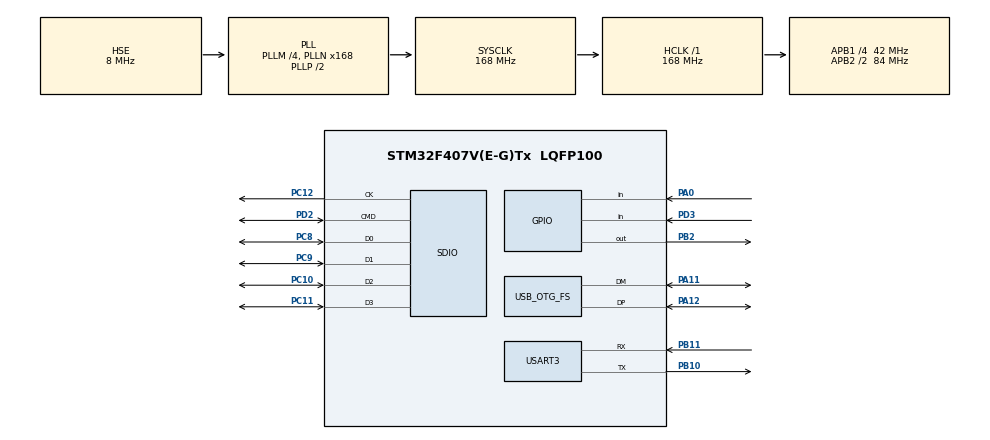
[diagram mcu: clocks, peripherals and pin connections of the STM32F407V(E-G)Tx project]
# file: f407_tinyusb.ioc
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Dma.Request0=USART3_RX
Dma.Request1=USART3_TX
Dma.USART3_RX.0.Direction=DMA_PERIPH_TO_MEMORY
Dma.USART3_RX.0.FIFOMode=DMA_FIFOMODE_DISABLE
Dma.USART3_RX.0.Instance=DMA1_Stream1
Dma.USART3_RX.0.MemDataAlignment=DMA_MDATAALIGN_BYTE
Dma.USART3_RX.0.MemInc=DMA_MINC_ENABLE
Dma.USART3_RX.0.Mode=DMA_NORMAL
Dma.USART3_RX.0.PeriphDataAlignment=DMA_PDATAALIGN_BYTE
Dma.USART3_RX.0.PeriphInc=DMA_PINC_DISABLE
Dma.USART3_RX.0.Priority=DMA_PRIORITY_LOW
Dma.USART3_TX.1.Direction=DMA_MEMORY_TO_PERIPH
Dma.USART3_TX.1.FIFOMode=DMA_FIFOMODE_DISABLE
Dma.USART3_TX.1.Instance=DMA1_Stream3
Dma.USART3_TX.1.MemDataAlignment=DMA_MDATAALIGN_BYTE
Dma.USART3_TX.1.MemInc=DMA_MINC_ENABLE
Dma.USART3_TX.1.Mode=DMA_NORMAL
Dma.USART3_TX.1.PeriphDataAlignment=DMA_PDATAALIGN_BYTE
Dma.USART3_TX.1.PeriphInc=DMA_PINC_DISABLE
Dma.USART3_TX.1.Priority=DMA_PRIORITY_LOW
FATFS.BSP.number=1
FATFS0.BSP.STBoard=false
FATFS0.BSP.api=Unknown
FATFS0.BSP.instance=PD3
FATFS0.BSP.ip=GPIO
FATFS0.BSP.mode=Input
FATFS0.BSP.name=Detect_SDIO
FATFS0.BSP.solution=PD3
Mcu.Family=STM32F4
Mcu.Name=STM32F407V(E-G)Tx
Mcu.Package=LQFP100
NVIC.DMA1_Stream1_IRQn=true\:0\:0\:false\:false\:true\:false\:true\:true
NVIC.DMA1_Stream3_IRQn=true\:0\:0\:false\:false\:true\:false\:true\:true
NVIC.PriorityGroup=NVIC_PRIORITYGROUP_4
NVIC.USART3_IRQn=true\:0\:0\:false\:false\:true\:true\:true\:true
PA0-WKUP.Signal=GPIO_Input
PA11.Mode=Device_Only
PA11.Signal=USB_OTG_FS_DM
PA12.Mode=Device_Only
PA12.Signal=USB_OTG_FS_DP
PB10.Mode=Asynchronous
PB10.Signal=USART3_TX
PB11.Mode=Asynchronous
PB11.Signal=USART3_RX
PB2.Signal=GPIO_Output
PC10.Mode=SD_4_bits_Wide_bus
PC10.Signal=SDIO_D2
PC11.Mode=SD_4_bits_Wide_bus
PC11.Signal=SDIO_D3
PC12.Mode=SD_4_bits_Wide_bus
PC12.Signal=SDIO_CK
PC8.Mode=SD_4_bits_Wide_bus
PC8.Signal=SDIO_D0
PC9.Mode=SD_4_bits_Wide_bus
PC9.Signal=SDIO_D1
PD2.Mode=SD_4_bits_Wide_bus
PD2.Signal=SDIO_CMD
PD3.Signal=GPIO_Input
PH0-OSC_IN.Mode=HSE-External-Oscillator
PH0-OSC_IN.Signal=RCC_OSC_IN
PH1-OSC_OUT.Mode=HSE-External-Oscillator
PH1-OSC_OUT.Signal=RCC_OSC_OUT
ProjectManager.HeapSize=0x200
ProjectManager.StackSize=0x400
ProjectManager.TargetToolchain=CMake
RCC.48MHZClocksFreq_Value=48000000
RCC.AHBFreq_Value=168000000
RCC.APB1CLKDivider=RCC_HCLK_DIV4
RCC.APB1Freq_Value=42000000
RCC.APB1TimFreq_Value=84000000
RCC.APB2CLKDivider=RCC_HCLK_DIV2
RCC.APB2Freq_Value=84000000
RCC.APB2TimFreq_Value=168000000
RCC.CortexFreq_Value=168000000
RCC.HCLKFreq_Value=168000000
RCC.HSE_VALUE=8000000
RCC.HSI_VALUE=16000000
RCC.LSE_VALUE=32768
RCC.PLLM=4
RCC.PLLN=168
RCC.PLLQ=7
RCC.PLLSourceVirtual=RCC_PLLSOURCE_HSE
RCC.SYSCLKFreq_VALUE=168000000
RCC.SYSCLKSource=RCC_SYSCLKSOURCE_PLLCLK
RCC.VCOOutputFreq_Value=336000000
USART3.VirtualMode=VM_ASYNC
USB_OTG_FS.VirtualMode=Device_Only
VP_FATFS_VS_SDIO.Mode=SDIO
board=custom

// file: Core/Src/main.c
/* USER CODE BEGIN Header */
/**
  ******************************************************************************
  * @file           : main.c
  * @brief          : Main program body
  ******************************************************************************
  * @attention
  *
  * Copyright (c) 2024 STMicroelectronics.
  * All rights reserved.
  *
  * This software is licensed under terms that can be found in the LICENSE file
  * in the root directory of this software component.
  * If no LICENSE file comes with this software, it is provided AS-IS.
  *
  ******************************************************************************
  */
/* USER CODE END Header */
#include "main.h"
#include "dma.h"
#include "fatfs.h"
#include "sdio.h"
#include "usart.h"
#include "usb_otg.h"
#include "gpio.h"

/* USER CODE BEGIN Includes */
#include "code.h"
#include "stdio.h"
/* USER CODE END Includes */

/* USER CODE BEGIN PTD */
int _write(int fd, char *ptr, int len)
{
    // HAL_UART_Transmit(&huart3, (uint8_t*)ptr, len, 0xFFFF); //huart是对应串
    HAL_UART_Transmit_DMA(&huart3, (uint8_t *)ptr, len);
    return len;
}
/* USER CODE END PTD */

void SystemClock_Config(void);

int main(void)
{

  /* MCU Configuration--------------------------------------------------------*/

  /* Reset of all peripherals, Initializes the Flash interface and the Systick. */
  HAL_Init();

  /* Configure the system clock */
  SystemClock_Config();

  /* Initialize all configured peripherals */
  MX_GPIO_Init();
  MX_DMA_Init();
  MX_USB_OTG_FS_PCD_Init();
  MX_USART3_UART_Init();
  MX_SDIO_SD_Init();
  MX_FATFS_Init();

  /* Infinite loop */
  while (1)
  {

    /* USER CODE BEGIN 3 */
    ToggleLed();

  }
  /* USER CODE END 3 */
}

void SystemClock_Config(void)
{
  RCC_OscInitTypeDef RCC_OscInitStruct = {0};
  RCC_ClkInitTypeDef RCC_ClkInitStruct = {0};

  /** Configure the main internal regulator output voltage
  */
  __HAL_RCC_PWR_CLK_ENABLE();
  __HAL_PWR_VOLTAGESCALING_CONFIG(PWR_REGULATOR_VOLTAGE_SCALE1);

  /** Initializes the RCC Oscillators according to the specified parameters
  * in the RCC_OscInitTypeDef structure.
  */
  RCC_OscInitStruct.OscillatorType = RCC_OSCILLATORTYPE_HSE;
  RCC_OscInitStruct.HSEState = RCC_HSE_ON;
  RCC_OscInitStruct.PLL.PLLState = RCC_PLL_ON;
  RCC_OscInitStruct.PLL.PLLSource = RCC_PLLSOURCE_HSE;
  RCC_OscInitStruct.PLL.PLLM = 4;
  RCC_OscInitStruct.PLL.PLLN = 168;
  RCC_OscInitStruct.PLL.PLLP = RCC_PLLP_DIV2;
  RCC_OscInitStruct.PLL.PLLQ = 7;
  if (HAL_RCC_OscConfig(&RCC_OscInitStruct) != HAL_OK)
  {
    Error_Handler();
  }

  /** Initializes the CPU, AHB and APB buses clocks
  */
  RCC_ClkInitStruct.ClockType = RCC_CLOCKTYPE_HCLK|RCC_CLOCKTYPE_SYSCLK
                              |RCC_CLOCKTYPE_PCLK1|RCC_CLOCKTYPE_PCLK2;
  RCC_ClkInitStruct.SYSCLKSource = RCC_SYSCLKSOURCE_PLLCLK;
  RCC_ClkInitStruct.AHBCLKDivider = RCC_SYSCLK_DIV1;
  RCC_ClkInitStruct.APB1CLKDivider = RCC_HCLK_DIV4;
  RCC_ClkInitStruct.APB2CLKDivider = RCC_HCLK_DIV2;

  if (HAL_RCC_ClockConfig(&RCC_ClkInitStruct, FLASH_LATENCY_5) != HAL_OK)
  {
    Error_Handler();
  }
}

void Error_Handler(void)
{
  __disable_irq();
  while (1)
  {
  }
}
